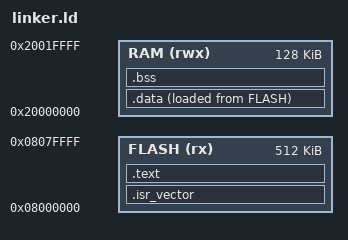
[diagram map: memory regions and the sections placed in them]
MEMORY
{
    FLASH (rx) : ORIGIN = 0x08000000, LENGTH = 512K
    RAM (rwx)  : ORIGIN = 0x20000000, LENGTH = 128K
}

SECTIONS
{
    .isr_vector :
    {
        . = ALIGN(4);
        KEEP(*(.isr_vector))
        . = ALIGN(4);
    } >FLASH

    .text :
    {
        . = ALIGN(4);
        *(.text)
        *(.text*)
        *(.rodata)
        *(.rodata*)
        . = ALIGN(4);
        _etext = .;
    } >FLASH

    _data_load = LOADADDR(.data);

    .data :
    {
        . = ALIGN(4);
        _data_start = .;
        *(.data)
        *(.data*)
        . = ALIGN(4);
        _data_end = .;
    } >RAM AT>FLASH

    .bss :
    {
        . = ALIGN(4);
        _bss_start = .;
        *(.bss)
        *(.bss*)
        *(COMMON)
        . = ALIGN(4);
        _bss_end = .;
    } >RAM

    _estack = ORIGIN(RAM) + LENGTH(RAM);
}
